# M2Sxxx register map
Vendor: Microsemi; Series: SmartFusion2; File version: 2.0.32
CPU: CM3 r2p1, little endian, MPU, no FPU, 4 interrupt priority bits
Registers are 32-bit, read-write, no defined reset value unless marked. A register's access mark holds for its fields unless they carry their own. Offsets are from the block's base; [hi:lo] are bit positions; {n}, {i} and the like mark numbered series.

## PDMA — No description provided for this peripheral
Base 0x40003000
0x00 RATIO_HIGH_LOW_Register — No description provided for this register
  [7:0] RATIOHILO — No description provided for this field
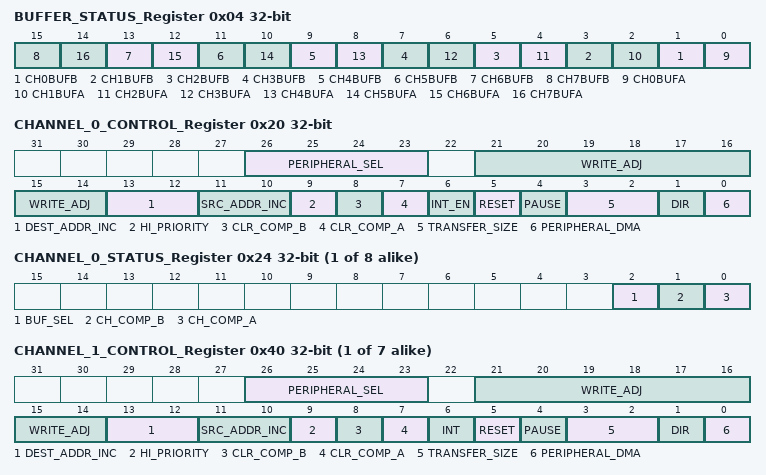
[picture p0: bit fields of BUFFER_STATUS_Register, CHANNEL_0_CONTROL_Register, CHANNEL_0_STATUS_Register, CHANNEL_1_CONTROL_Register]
0x04 BUFFER_STATUS_Register — No description provided for this register
  [2n+1] CH{n}BUFB ro (n=0..7) — No description provided for this field
  [2n] CH{n}BUFA ro (n=0..7) — No description provided for this field
0x20 CHANNEL_0_CONTROL_Register — No description provided for this register
  [26:23] PERIPHERAL_SEL — No description provided for this field
  [21:14] WRITE_ADJ — No description provided for this field
  [13:12] DEST_ADDR_INC — No description provided for this field
  [11:10] SRC_ADDR_INC — No description provided for this field
  [9] HI_PRIORITY — No description provided for this field
  [8] CLR_COMP_B — No description provided for this field
  [7] CLR_COMP_A — No description provided for this field
  [6] INT_EN — No description provided for this field
  [5] RESET — No description provided for this field
  [4] PAUSE — No description provided for this field
  [3:2] TRANSFER_SIZE — No description provided for this field
  [1] DIR — No description provided for this field
  [0] PERIPHERAL_DMA — No description provided for this field
{0x24+0x20*i} CHANNEL_{i}_STATUS_Register (i=0..7) — No description provided for this register
  [2] BUF_SEL ro — No description provided for this field
  [1] CH_COMP_B ro — No description provided for this field
  [0] CH_COMP_A ro — No description provided for this field
{0x28+0x20*i} CHANNEL_{i}_BUFFER_A_SRC_ADDR_Register (i=0..7) — No description provided for this register
  [31:0] BUF_A_SRC — No description provided for this field
{0x2C+0x20*i} CHANNEL_{i}_BUFFER_A_DST_ADDR_Register (i=0..7) — No description provided for this register
  [31:0] BUF_A_DST — No description provided for this field
{0x30+0x20*i} CHANNEL_{i}_BUFFER_A_TRANSFER_COUNT_Register (i=0..7) — No description provided for this register
  [15:0] BUF_A_COUNT — No description provided for this field
{0x34+0x20*i} CHANNEL_{i}_BUFFER_B_SRC_ADDR_Register (i=0..7) — No description provided for this register
  [31:0] BUF_B_SRC — No description provided for this field
{0x38+0x20*i} CHANNEL_{i}_BUFFER_B_DST_ADDR_Register (i=0..7) — No description provided for this register
  [31:0] BUF_B_DST — No description provided for this field
{0x3C+0x20*i} CHANNEL_{i}_BUFFER_B_TRANSFER_COUNT_Register (i=0..7) — No description provided for this register
  [15:0] BUF_B_COUNT — No description provided for this field
{0x20+0x20*i} CHANNEL_{i}_CONTROL_Register (i=1..7) — No description provided for this register
  [26:23] PERIPHERAL_SEL — No description provided for this field
  [21:14] WRITE_ADJ — No description provided for this field
  [13:12] DEST_ADDR_INC — No description provided for this field
  [11:10] SRC_ADDR_INC — No description provided for this field
  [9] HI_PRIORITY — No description provided for this field
  [8] CLR_COMP_B — No description provided for this field
  [7] CLR_COMP_A — No description provided for this field
  [6] INT — No description provided for this field
  [5] RESET — No description provided for this field
  [4] PAUSE — No description provided for this field
  [3:2] TRANSFER_SIZE — No description provided for this field
  [1] DIR — No description provided for this field
  [0] PERIPHERAL_DMA — No description provided for this field

## COMBLK — No description provided for this peripheral
Base 0x40016000
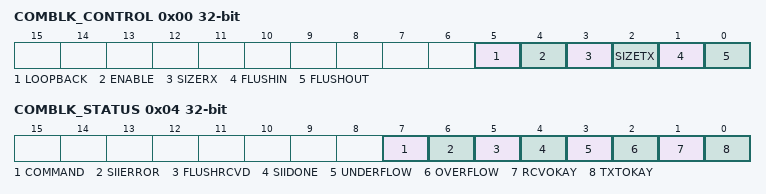
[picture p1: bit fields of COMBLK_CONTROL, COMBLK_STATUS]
0x00 COMBLK_CONTROL — No description provided for this register
  [5] LOOPBACK — No description provided for this field
  [4] ENABLE — No description provided for this field
  [3] SIZERX — No description provided for this field
  [2] SIZETX — No description provided for this field
  [1] FLUSHIN — No description provided for this field
  [0] FLUSHOUT — No description provided for this field
0x04 COMBLK_STATUS — No description provided for this register
  [7] COMMAND — No description provided for this field
  [6] SIIERROR — No description provided for this field
  [5] FLUSHRCVD — No description provided for this field
  [4] SIIDONE — No description provided for this field
  [3] UNDERFLOW — No description provided for this field
  [2] OVERFLOW — No description provided for this field
  [1] RCVOKAY — No description provided for this field
  [0] TXTOKAY — No description provided for this field
0x08 INTENABLE — No description provided for this register
  [7:0] ENABLE — No description provided for this field
0x10 Data8 — No description provided for this register
  [7:0] DATA8 — No description provided for this field
0x14 Data32 — No description provided for this register
  [31:0] DATA32 — No description provided for this field
0x18 FRAME_START8 — No description provided for this register
  [31:0] Frame_Start8 — No description provided for this field
0x1C FRAME_START32 — No description provided for this register
  [31:0] Frame_Start32 — No description provided for this field
